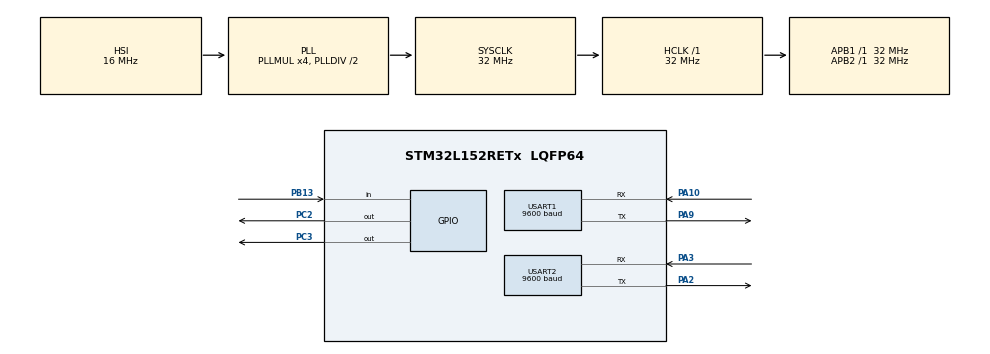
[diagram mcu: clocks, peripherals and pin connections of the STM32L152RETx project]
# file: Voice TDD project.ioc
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Mcu.Family=STM32L1
RCC.MSI_VALUE=2097000
FREERTOS.Tasks01=defaultTask,0,128,StartDefaultTask,Default,NULL,Dynamic,NULL,NULL
PA10.Mode=Asynchronous
USART1.BaudRate=9600
PC2.Signal=GPIO_Output
VP_TIM6_VS_ClockSourceINT.Mode=Enable_Timer
PC2.GPIO_Speed=GPIO_SPEED_FREQ_VERY_HIGH
PB13.Signal=GPIO_Input
USART2.BaudRate=9600
PC3.GPIO_Speed=GPIO_SPEED_FREQ_VERY_HIGH
RCC.SYSCLKSource=RCC_SYSCLKSOURCE_PLLCLK
ProjectManager.StackSize=0x400
PC3.PinState=GPIO_PIN_SET
NVIC.TIM6_IRQn=true\:7\:0\:true\:false\:true\:false\:true\:true
PA3.Mode=Asynchronous
PA9.Mode=Asynchronous
VP_SYS_VS_tim3.Mode=TIM3
ProjectManager.TargetToolchain=STM32CubeIDE
RCC.HCLKFreq_Value=32000000
RCC.APB2TimFreq_Value=32000000
PA9.Signal=USART1_TX
PC3.Signal=GPIO_Output
RCC.LSE_VALUE=32768
RCC.AHBFreq_Value=32000000
RCC.HSE_VALUE=24000000
FREERTOS.configUSE_TIMERS=1
board=custom
RCC.VCOOutputFreq_Value=64000000
RCC.PLLMUL=RCC_PLL_MUL4
NVIC.TIM3_IRQn=true\:0\:0\:false\:false\:true\:false\:false\:true
PB13.GPIO_PuPd=GPIO_PULLDOWN
RCC.APB2Freq_Value=32000000
TIM6.TIM_MasterOutputTrigger=TIM_TRGO_RESET
PC2.GPIO_PuPd=GPIO_PULLDOWN
TIM6.Period=31999
VP_FREERTOS_VS_CMSIS_V1.Mode=CMSIS_V1
Mcu.Name=STM32L152RETx
PA2.Signal=USART2_TX
RCC.48MHZClocksFreq_Value=32000000
RCC.SYSCLKFreq_VALUE=32000000
Mcu.Package=LQFP64
NVIC.TimeBase=TIM3_IRQn
PC2.PinState=GPIO_PIN_SET
USART2.VirtualMode=VM_ASYNC
USART1.VirtualMode=VM_ASYNC
NVIC.TimeBaseIP=TIM3
PA10.Signal=USART1_RX
ProjectManager.HeapSize=0x200
RCC.HSI_VALUE=16000000
NVIC.PriorityGroup=NVIC_PRIORITYGROUP_4
RCC.APB1TimFreq_Value=32000000
PA2.Mode=Asynchronous
RCC.APB1Freq_Value=32000000
PC3.GPIO_PuPd=GPIO_PULLDOWN
PA3.Signal=USART2_RX

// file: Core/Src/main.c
/* USER CODE BEGIN Header */
/**
  ******************************************************************************
  * @file           : main.c
  * @brief          : Main program body
  ******************************************************************************
  * @attention
  *
  * <h2><center>&copy; Copyright (c) 2022 STMicroelectronics.
  * All rights reserved.</center></h2>
  *
  * This software component is licensed by ST under BSD 3-Clause license,
  * the "License"; You may not use this file except in compliance with the
  * License. You may obtain a copy of the License at:
  *                        opensource.org/licenses/BSD-3-Clause
  *
  ******************************************************************************
  */
#ifndef TEST
/* USER CODE END Header */
#include "main.h"
#include "cmsis_os.h"

/* USER CODE BEGIN Includes */

#else
#include "unity.h"
#include "mock_main.h"
#include "TestableMain.h"
#endif

#include "LED.h"
#include "LEDTask.h"
#include "VoiceTask.h"
#include "Utils.h"

/* USER CODE END Includes */

#ifndef TEST
TIM_HandleTypeDef htim6;

UART_HandleTypeDef huart1;
UART_HandleTypeDef huart2;
#endif

//osThreadId defaultTaskHandle;
/* USER CODE BEGIN PV */
TaskHandle_t xHandle_LED;
TaskHandle_t xHandle_LEDToggle;
TaskHandle_t xHandle_VoiceTask;
/*TaskHandle_t xHandle_VoiceStopRecord;
TaskHandle_t xHandle_VoiceStartPlay;
TaskHandle_t xHandle_VoiceStopPlay;*/
/* USER CODE END PV */

void SystemClock_Config(void);
static void MX_GPIO_Init(void);
static void MX_USART2_UART_Init(void);
static void MX_TIM6_Init(void);
static void MX_USART1_UART_Init(void);
void StartDefaultTask(void const * argument);

/* USER CODE BEGIN 0 */
#ifdef TEST
void TestableMain(void)
#else
/* USER CODE END 0 */

int main(void)
  /* USER CODE BEGIN 1 */
#endif
{
  /* USER CODE END 1 */

  /* MCU Configuration--------------------------------------------------------*/

  /* Reset of all peripherals, Initializes the Flash interface and the Systick. */
  HAL_Init();

  /* Configure the system clock */
  SystemClock_Config();

  /* Initialize all configured peripherals */
  MX_GPIO_Init();
  MX_USART2_UART_Init();
  MX_TIM6_Init();
  MX_USART1_UART_Init();

  /* Create the thread(s) */
  /* definition and creation of defaultTask */
  //osThreadDef(defaultTask, StartDefaultTask, osPriorityNormal, 0, 128);
  //defaultTaskHandle = osThreadCreate(osThread(defaultTask), NULL);

  /* Start scheduler */
  //osKernelStart();

  /* We should never get here as control is now taken by the scheduler */
  /* Infinite loop */
  /* USER CODE BEGIN WHILE */
  LED_Init();

  HAL_TIM_Base_Start_IT(&htim6);

  Power_On();

  if( xTaskCreate(prvLEDTask, "LEDTask", configMINIMAL_STACK_SIZE, /*(void *)&LEDParam*/NULL, tskIDLE_PRIORITY, &xHandle_LED) != pdPASS){
  	  HAL_UART_Transmit(&huart2, "LEDTask creating ERROR !!!\r\n", 32, 100 );
  }

  if( xTaskCreate(prvLEDToggleTask, "LEDTask", configMINIMAL_STACK_SIZE, /*(void *)&LEDParam*/NULL, tskIDLE_PRIORITY, &xHandle_LEDToggle) != pdPASS){
      HAL_UART_Transmit(&huart2, "LEDToggleTask creating ERROR !!!\r\n", 32, 100 );
  }

  if( xTaskCreate(prvVoiceTask, "VoiceTask", configMINIMAL_STACK_SIZE, /*(void *)&LEDParam*/NULL, tskIDLE_PRIORITY, &xHandle_VoiceTask) != pdPASS){
        HAL_UART_Transmit(&huart2, "VoiceTask creating ERROR !!!\r\n", 31, 100 );
  }

  /*if( xTaskCreate(prvVoiceTaskStopRecord, "VoiceTaskStopREcord", configMINIMAL_STACK_SIZE, //(void *)&LEDParamNULL, tskIDLE_PRIORITY, &xHandle_VoiceStopRecord) != pdPASS){
          HAL_UART_Transmit(&huart2, "VoiceTaskStopRecord creating ERROR !!!\r\n", 42, 100 );
  }

  if( xTaskCreate(prvVoiceTaskStartPlay, "VoiceTaskStartPlay", configMINIMAL_STACK_SIZE, //(void *)&LEDParamNULL, tskIDLE_PRIORITY, &xHandle_VoiceStartPlay) != pdPASS){
          HAL_UART_Transmit(&huart2, "VoiceTaskStartRecord creating ERROR !!!\r\n", 42, 100 );
  }

    if( xTaskCreate(prvVoiceTaskStopRecord, "VoiceTaskStopPlay", configMINIMAL_STACK_SIZE, //(void *)&LEDParamNULL, tskIDLE_PRIORITY, &xHandle_VoiceStopPlay) != pdPASS){
            HAL_UART_Transmit(&huart2, "VoiceTaskStopRecord creating ERROR !!!\r\n", 42, 100 );
    }*/

  vTaskStartScheduler();

  while (1)
  {
    /* USER CODE END WHILE */

    /* USER CODE BEGIN 3 */
  }
//#endif
  /* USER CODE END 3 */
}

void SystemClock_Config(void)
{
  RCC_OscInitTypeDef RCC_OscInitStruct = {0};
  RCC_ClkInitTypeDef RCC_ClkInitStruct = {0};

  /** Configure the main internal regulator output voltage
  */
  __HAL_PWR_VOLTAGESCALING_CONFIG(PWR_REGULATOR_VOLTAGE_SCALE1);
  /** Initializes the RCC Oscillators according to the specified parameters
  * in the RCC_OscInitTypeDef structure.
  */
  RCC_OscInitStruct.OscillatorType = RCC_OSCILLATORTYPE_HSI;
  RCC_OscInitStruct.HSIState = RCC_HSI_ON;
  RCC_OscInitStruct.HSICalibrationValue = RCC_HSICALIBRATION_DEFAULT;
  RCC_OscInitStruct.PLL.PLLState = RCC_PLL_ON;
  RCC_OscInitStruct.PLL.PLLSource = RCC_PLLSOURCE_HSI;
  RCC_OscInitStruct.PLL.PLLMUL = RCC_PLL_MUL4;
  RCC_OscInitStruct.PLL.PLLDIV = RCC_PLL_DIV2;
  if (HAL_RCC_OscConfig(&RCC_OscInitStruct) != HAL_OK)
  {
    Error_Handler();
  }
  /** Initializes the CPU, AHB and APB buses clocks
  */
  RCC_ClkInitStruct.ClockType = RCC_CLOCKTYPE_HCLK|RCC_CLOCKTYPE_SYSCLK
                              |RCC_CLOCKTYPE_PCLK1|RCC_CLOCKTYPE_PCLK2;
  RCC_ClkInitStruct.SYSCLKSource = RCC_SYSCLKSOURCE_PLLCLK;
  RCC_ClkInitStruct.AHBCLKDivider = RCC_SYSCLK_DIV1;
  RCC_ClkInitStruct.APB1CLKDivider = RCC_HCLK_DIV1;
  RCC_ClkInitStruct.APB2CLKDivider = RCC_HCLK_DIV1;

  if (HAL_RCC_ClockConfig(&RCC_ClkInitStruct, FLASH_LATENCY_1) != HAL_OK)
  {
    Error_Handler();
  }
}

static void MX_TIM6_Init(void)
{

  TIM_MasterConfigTypeDef sMasterConfig = {0};

  htim6.Instance = TIM6;
  htim6.Init.Prescaler = 0;
  htim6.Init.CounterMode = TIM_COUNTERMODE_UP;
  htim6.Init.Period = 31999;
  htim6.Init.AutoReloadPreload = TIM_AUTORELOAD_PRELOAD_DISABLE;
  if (HAL_TIM_Base_Init(&htim6) != HAL_OK)
  {
    Error_Handler();
  }
  sMasterConfig.MasterOutputTrigger = TIM_TRGO_RESET;
  sMasterConfig.MasterSlaveMode = TIM_MASTERSLAVEMODE_DISABLE;
  if (HAL_TIMEx_MasterConfigSynchronization(&htim6, &sMasterConfig) != HAL_OK)
  {
    Error_Handler();
  }

}

static void MX_USART1_UART_Init(void)
{

  huart1.Instance = USART1;
  huart1.Init.BaudRate = 9600;
  huart1.Init.WordLength = UART_WORDLENGTH_8B;
  huart1.Init.StopBits = UART_STOPBITS_1;
  huart1.Init.Parity = UART_PARITY_NONE;
  huart1.Init.Mode = UART_MODE_TX_RX;
  huart1.Init.HwFlowCtl = UART_HWCONTROL_NONE;
  huart1.Init.OverSampling = UART_OVERSAMPLING_16;
  if (HAL_UART_Init(&huart1) != HAL_OK)
  {
    Error_Handler();
  }

}

static void MX_USART2_UART_Init(void)
{

  huart2.Instance = USART2;
  huart2.Init.BaudRate = 9600;
  huart2.Init.WordLength = UART_WORDLENGTH_8B;
  huart2.Init.StopBits = UART_STOPBITS_1;
  huart2.Init.Parity = UART_PARITY_NONE;
  huart2.Init.Mode = UART_MODE_TX_RX;
  huart2.Init.HwFlowCtl = UART_HWCONTROL_NONE;
  huart2.Init.OverSampling = UART_OVERSAMPLING_16;
  if (HAL_UART_Init(&huart2) != HAL_OK)
  {
    Error_Handler();
  }

}

static void MX_GPIO_Init(void)
{
  GPIO_InitTypeDef GPIO_InitStruct = {0};

  /* GPIO Ports Clock Enable */
  __HAL_RCC_GPIOC_CLK_ENABLE();
  __HAL_RCC_GPIOA_CLK_ENABLE();
  __HAL_RCC_GPIOB_CLK_ENABLE();

  /*Configure GPIO pin Output Level */
  HAL_GPIO_WritePin(GPIOC, GPIO_PIN_2|GPIO_PIN_3|GPIO_PIN_7, GPIO_PIN_SET);

  /*Configure GPIO pins : PC2 PC3 PC7 */
  GPIO_InitStruct.Pin = GPIO_PIN_2|GPIO_PIN_3|GPIO_PIN_7;
  GPIO_InitStruct.Mode = GPIO_MODE_OUTPUT_PP;
  GPIO_InitStruct.Pull = GPIO_PULLDOWN;
  GPIO_InitStruct.Speed = GPIO_SPEED_FREQ_VERY_HIGH;
  HAL_GPIO_Init(GPIOC, &GPIO_InitStruct);

  /*Configure GPIO pin : PB13 */
  GPIO_InitStruct.Pin = GPIO_PIN_13;
  GPIO_InitStruct.Mode = GPIO_MODE_INPUT;
  GPIO_InitStruct.Pull = GPIO_PULLDOWN;
  HAL_GPIO_Init(GPIOB, &GPIO_InitStruct);

}

void StartDefaultTask(void const * argument)
{
  for(;;)
  {
    osDelay(1);
  }
}

void HAL_TIM_PeriodElapsedCallback(TIM_HandleTypeDef *htim)
{
  if (htim->Instance == TIM3) {
    HAL_IncTick();
  }
}

void Error_Handler(void)
{
}

/************************ (C) COPYRIGHT STMicroelectronics *****END OF FILE****/
